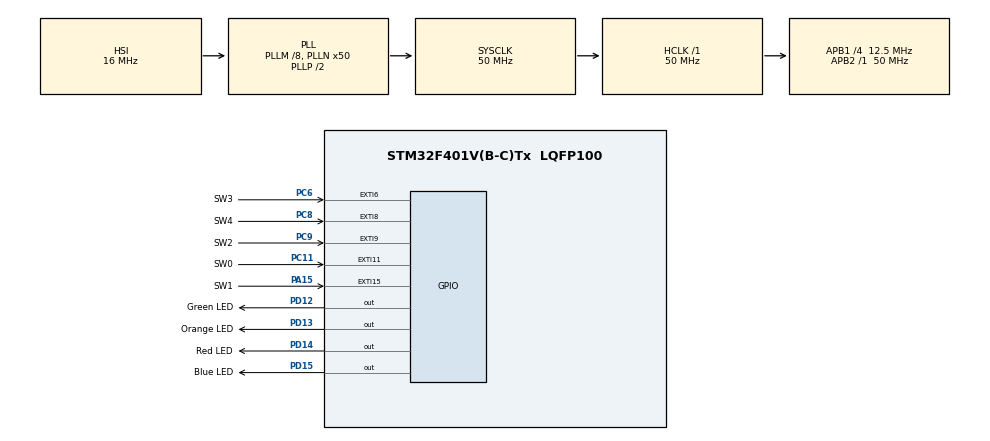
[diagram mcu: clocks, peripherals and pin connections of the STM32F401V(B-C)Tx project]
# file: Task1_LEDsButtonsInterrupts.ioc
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Mcu.Family=STM32F4
PD12.GPIO_Label=Green LED
RCC.CortexFreq_Value=50000000
PD15.GPIO_Label=Blue LED
PC9.GPIO_Label=SW2
PC11.Signal=GPXTI11
PC8.Signal=GPXTI8
PC6.Signal=GPXTI6
PC6.GPIO_Label=SW3
RCC.APB1CLKDivider=RCC_HCLK_DIV4
RCC.SYSCLKSource=RCC_SYSCLKSOURCE_PLLCLK
ProjectManager.StackSize=0x400
PC8.GPIO_Label=SW4
PD13.Signal=GPIO_Output
PA15.GPIO_Label=SW1
ProjectManager.TargetToolchain=STM32CubeIDE
RCC.HCLKFreq_Value=50000000
RCC.APB2TimFreq_Value=50000000
RCC.LSE_VALUE=32768
RCC.AHBFreq_Value=50000000
NVIC.EXTI15_10_IRQn=true\:0\:0\:false\:false\:true\:true\:true
RCC.HSE_VALUE=8000000
board=STM32F401C-DISCO
RCC.VCOOutputFreq_Value=100000000
RCC.APB2Freq_Value=50000000
PC11.GPIO_Label=SW0
PD14.GPIO_Label=Red LED
Mcu.Name=STM32F401V(B-C)Tx
PD14.Signal=GPIO_Output
RCC.48MHZClocksFreq_Value=14285714.285714285
RCC.SYSCLKFreq_VALUE=50000000
PD13.GPIO_Label=Orange LED
Mcu.Package=LQFP100
PD12.Signal=GPIO_Output
NVIC.EXTI9_5_IRQn=true\:0\:0\:false\:false\:true\:true\:true
PA15.Signal=GPXTI15
ProjectManager.HeapSize=0x200
RCC.HSI_VALUE=16000000
RCC.PLLQ=7
NVIC.PriorityGroup=NVIC_PRIORITYGROUP_0
RCC.PLLM=8
RCC.PLLN=50
RCC.APB1TimFreq_Value=25000000
PC9.Signal=GPXTI9
RCC.APB1Freq_Value=12500000
PD15.Signal=GPIO_Output

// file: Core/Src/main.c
/* USER CODE BEGIN Header */
/**
  ******************************************************************************
  * @file           : main.c
  * @brief          : Main program body
  ******************************************************************************
  * @attention
  *
  * <h2><center>&copy; Copyright (c) 2021 STMicroelectronics.
  * All rights reserved.</center></h2>
  *
  * This software component is licensed by ST under BSD 3-Clause license,
  * the "License"; You may not use this file except in compliance with the
  * License. You may obtain a copy of the License at:
  *                        opensource.org/licenses/BSD-3-Clause
  *
  ******************************************************************************
  */
/* USER CODE END Header */
#include "main.h"

/* USER CODE BEGIN Includes */
#include "ledManager.h"
/* USER CODE END Includes */

void SystemClock_Config(void);
static void MX_GPIO_Init(void);

int main(void)
{

  /* MCU Configuration--------------------------------------------------------*/

  /* Reset of all peripherals, Initializes the Flash interface and the Systick. */
  HAL_Init();

  /* Configure the system clock */
  SystemClock_Config();

  /* Initialize all configured peripherals */
  MX_GPIO_Init();

  /* Infinite loop */
  while (1)
  {
	RunLEDsSchema();
  }
}

void SystemClock_Config(void)
{
  RCC_OscInitTypeDef RCC_OscInitStruct = {0};
  RCC_ClkInitTypeDef RCC_ClkInitStruct = {0};

  /** Configure the main internal regulator output voltage
  */
  __HAL_RCC_PWR_CLK_ENABLE();
  __HAL_PWR_VOLTAGESCALING_CONFIG(PWR_REGULATOR_VOLTAGE_SCALE2);
  /** Initializes the RCC Oscillators according to the specified parameters
  * in the RCC_OscInitTypeDef structure.
  */
  RCC_OscInitStruct.OscillatorType = RCC_OSCILLATORTYPE_HSI;
  RCC_OscInitStruct.HSIState = RCC_HSI_ON;
  RCC_OscInitStruct.HSICalibrationValue = RCC_HSICALIBRATION_DEFAULT;
  RCC_OscInitStruct.PLL.PLLState = RCC_PLL_ON;
  RCC_OscInitStruct.PLL.PLLSource = RCC_PLLSOURCE_HSI;
  RCC_OscInitStruct.PLL.PLLM = 8;
  RCC_OscInitStruct.PLL.PLLN = 50;
  RCC_OscInitStruct.PLL.PLLP = RCC_PLLP_DIV2;
  RCC_OscInitStruct.PLL.PLLQ = 7;
  if (HAL_RCC_OscConfig(&RCC_OscInitStruct) != HAL_OK)
  {
    Error_Handler();
  }
  /** Initializes the CPU, AHB and APB buses clocks
  */
  RCC_ClkInitStruct.ClockType = RCC_CLOCKTYPE_HCLK|RCC_CLOCKTYPE_SYSCLK
                              |RCC_CLOCKTYPE_PCLK1|RCC_CLOCKTYPE_PCLK2;
  RCC_ClkInitStruct.SYSCLKSource = RCC_SYSCLKSOURCE_PLLCLK;
  RCC_ClkInitStruct.AHBCLKDivider = RCC_SYSCLK_DIV1;
  RCC_ClkInitStruct.APB1CLKDivider = RCC_HCLK_DIV4;
  RCC_ClkInitStruct.APB2CLKDivider = RCC_HCLK_DIV1;

  if (HAL_RCC_ClockConfig(&RCC_ClkInitStruct, FLASH_LATENCY_1) != HAL_OK)
  {
    Error_Handler();
  }
}

static void MX_GPIO_Init(void)
{
  GPIO_InitTypeDef GPIO_InitStruct = {0};

  /* GPIO Ports Clock Enable */
  __HAL_RCC_GPIOD_CLK_ENABLE();
  __HAL_RCC_GPIOC_CLK_ENABLE();
  __HAL_RCC_GPIOA_CLK_ENABLE();

  /*Configure GPIO pin Output Level */
  HAL_GPIO_WritePin(GPIOD, Green_LED_Pin|Orange_LED_Pin|Red_LED_Pin|Blue_LED_Pin, GPIO_PIN_RESET);

  /*Configure GPIO pins : Green_LED_Pin Orange_LED_Pin Red_LED_Pin Blue_LED_Pin */
  GPIO_InitStruct.Pin = Green_LED_Pin|Orange_LED_Pin|Red_LED_Pin|Blue_LED_Pin;
  GPIO_InitStruct.Mode = GPIO_MODE_OUTPUT_PP;
  GPIO_InitStruct.Pull = GPIO_NOPULL;
  GPIO_InitStruct.Speed = GPIO_SPEED_FREQ_LOW;
  HAL_GPIO_Init(GPIOD, &GPIO_InitStruct);

  /*Configure GPIO pins : SW3_Pin SW4_Pin SW2_Pin SW0_Pin */
  GPIO_InitStruct.Pin = SW3_Pin|SW4_Pin|SW2_Pin|SW0_Pin;
  GPIO_InitStruct.Mode = GPIO_MODE_IT_RISING;
  GPIO_InitStruct.Pull = GPIO_NOPULL;
  HAL_GPIO_Init(GPIOC, &GPIO_InitStruct);

  /*Configure GPIO pin : SW1_Pin */
  GPIO_InitStruct.Pin = SW1_Pin;
  GPIO_InitStruct.Mode = GPIO_MODE_IT_RISING;
  GPIO_InitStruct.Pull = GPIO_NOPULL;
  HAL_GPIO_Init(SW1_GPIO_Port, &GPIO_InitStruct);

  /* EXTI interrupt init*/
  HAL_NVIC_SetPriority(EXTI9_5_IRQn, 0, 0);
  HAL_NVIC_EnableIRQ(EXTI9_5_IRQn);

  HAL_NVIC_SetPriority(EXTI15_10_IRQn, 0, 0);
  HAL_NVIC_EnableIRQ(EXTI15_10_IRQn);

}

void Error_Handler(void)
{
  __disable_irq();
  while (1)
  {
  }
}

/************************ (C) COPYRIGHT STMicroelectronics *****END OF FILE****/
